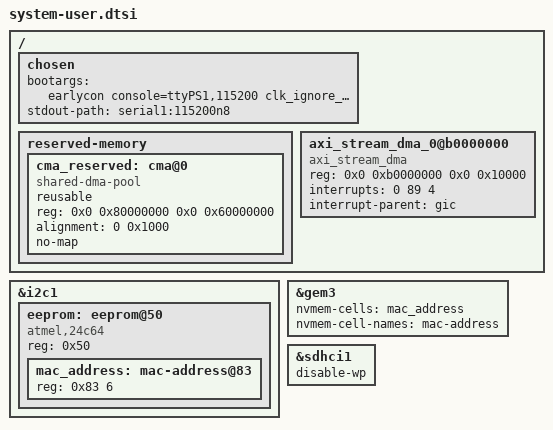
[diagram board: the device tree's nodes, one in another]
/ {
	chosen {
		bootargs = " earlycon console=ttyPS1,115200 clk_ignore_unused root=/dev/ram0 rw net.ifnames=0 biosdevname=0 cma=1536M";
		stdout-path = "serial1:115200n8";
	};

	reserved-memory {
		#address-cells = <2>;
		#size-cells = <2>;
		ranges;

		cma_reserved: cma@0 {
			compatible = "shared-dma-pool";
			reusable;
			reg = <0x0 0x80000000 0x0 0x60000000>; /* 1.5 GB reserved at 2GB boundary */
			alignment = <0 0x1000>;
			no-map;
		};
	};
};
&i2c1 {
	eeprom: eeprom@50 {
		#address-cells = <1>;
		#size-cells = <1>;
		compatible = "atmel,24c64";
		reg = <0x50>;
		mac_address: mac-address@83 {
			reg = <0x83 6>;
		};
	};
};
&gem3 {
	nvmem-cells = <&mac_address>;
	nvmem-cell-names = "mac-address";
};
&sdhci1 {
	status = "okay";
	disable-wp;
};
/ {
	axi_stream_dma_0@b0000000 {
		compatible = "axi_stream_dma";
		reg = <0x0 0xb0000000 0x0 0x10000>;
		interrupts = <0 89 4>;
		interrupt-parent = <&gic>;
	};
};
